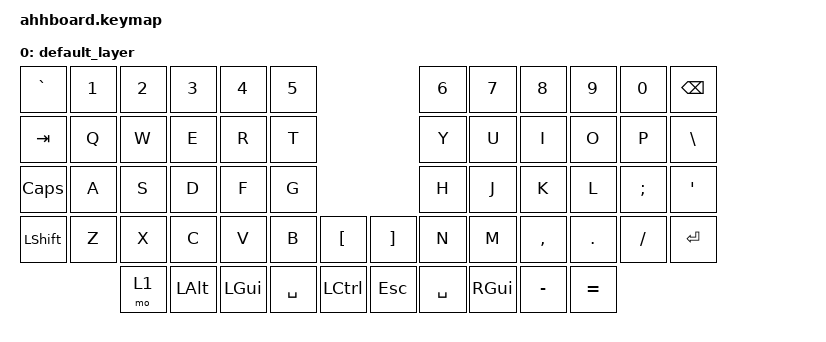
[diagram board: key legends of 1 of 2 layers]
#include <behaviors.dtsi>
#include <dt-bindings/zmk/keys.h>
#include <dt-bindings/zmk/bt.h>

/ {
        keymap {
                compatible = "zmk,keymap";

                default_layer {
// ---------------------------------------------------------------------------------
// |   `  |  1  |  2  |  3  |  4  |  5  |      |     |      |  6  |  7  |  8  |  9  |  0  | BKSP |
// |  TAB |  Q  |  W  |  E  |  R  |  T  |      |     |      |  Y  |  U  |  I  |  O  |  P  |  \   |
// | CAPS |  A  |  S  |  D  |  F  |  G  |      |     |      |  H  |  J  |  K  |  L  |  ;  | APOS |
// | SHFT |  Z  |  X  |  C  |  V  |  B  | LBKT |     | RBKT |  N  |  M  |  ,  |  .  |  /  | RET  |
// |      |     | FN  | ALT | CMD | SPC | CTRL |     | ESC  | SPC | CMD |MINUS|EQUAL|     |      |
                        bindings = <
   &kp GRAVE  &kp N1    &kp N2    &kp N3     &kp N4     &kp N5                                 &kp N6     &kp N7    &kp N8     &kp N9    &kp N0    &kp BSPC
   &kp TAB    &kp Q     &kp W     &kp E      &kp R      &kp T                                  &kp Y      &kp U     &kp I      &kp O     &kp P     &kp BSLH
   &kp CAPS   &kp A     &kp S     &kp D      &kp F      &kp G                                  &kp H      &kp J     &kp K      &kp L     &kp SEMI  &kp APOS
   &kp LSHFT  &kp Z     &kp X     &kp C      &kp V      &kp B      &kp LBKT        &kp RBKT    &kp N      &kp M     &kp COMMA  &kp DOT   &kp FSLH  &kp RET
                        &mo 1     &kp LALT   &kp LGUI   &kp SPACE  &kp LCTRL       &kp ESC     &kp SPACE  &kp RGUI  &kp MINUS  &kp EQUAL  
                        >;
                };
                lower_layer {
// ------------------------------------------------------------------------------------------------------------
// | BT0   |  BT1  |  BT2  |  BT3  |  BT4  |  BT5  |                   |  F1   |  F2   |   F3  |  F4   |  F5   | F6    |
// | BT_CLR|       |       |       |       |       |                   |  F7   |  F8   |   F9  |  F10  |  F11  | F12   |
// |       |       |       | LPAR  | RPAR  |       |     |       |     |       | LBKT  | RBKT  |       |       |       |
// |       |       |       |       |       |       |     |       |     |       |       |       |       |       |       |
                        bindings = <
   &bt BT_SEL 0   &bt BT_SEL 1   &bt BT_SEL 2   &bt BT_SEL 3   &bt BT_SEL 4                       &kp F1    &kp F2    &kp F3   &kp F4      &kp F5     &kp F6    
   &bt BT_CLR     &trans         &trans         &trans         &trans                             &kp F7    &kp F8    &kp F9   &kp F10     &kp F11    &kp F12   
   &trans         &trans         &kp LPAR       &kp RPAR       &trans                             &trans    &kp LBKT  &kp RBKT &trans      &trans     &trans 
   &trans         &trans         &trans         &trans         &trans        &trans    &trans     &trans    &trans    &trans   &trans      &trans     &trans   
                                 &trans         &trans         &trans        &trans    &trans     &trans    &trans    &trans   &trans     
                        >;
                };
        };
};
